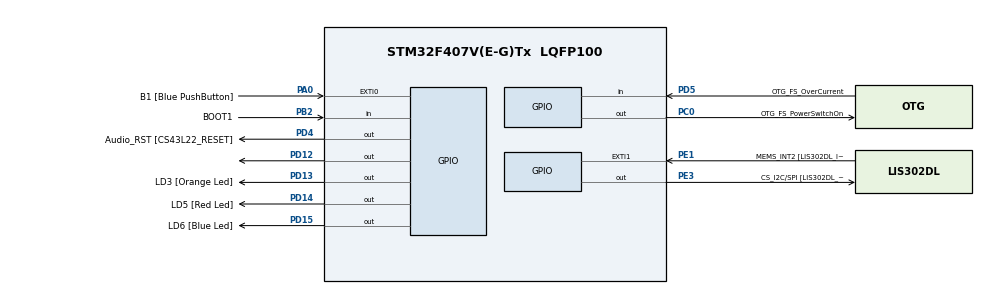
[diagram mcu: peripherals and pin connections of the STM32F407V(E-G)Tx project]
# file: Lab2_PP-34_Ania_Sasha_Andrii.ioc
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Mcu.Family=STM32F4
Mcu.Name=STM32F407V(E-G)Tx
Mcu.Package=LQFP100
NVIC.EXTI0_IRQn=true\:0\:0\:false\:false\:true\:true\:true\:true
NVIC.PriorityGroup=NVIC_PRIORITYGROUP_0
PA0-WKUP.GPIO_Label=B1 [Blue PushButton]
PA0-WKUP.GPIO_ModeDefaultEXTI=GPIO_MODE_IT_RISING_FALLING
PA0-WKUP.Signal=GPXTI0
PA10.GPIO_Label=OTG_FS_ID
PA10.GPIO_Mode=GPIO_MODE_AF_PP
PA10.GPIO_PuPd=GPIO_NOPULL
PA10.GPIO_Speed=GPIO_SPEED_FREQ_LOW
PA10.Signal=USB_OTG_FS_ID
PA11.GPIO_Label=OTG_FS_DM
PA11.GPIO_Mode=GPIO_MODE_AF_PP
PA11.GPIO_PuPd=GPIO_NOPULL
PA11.GPIO_Speed=GPIO_SPEED_FREQ_LOW
PA11.Signal=USB_OTG_FS_DM
PA12.GPIO_Label=OTG_FS_DP
PA12.GPIO_Mode=GPIO_MODE_AF_PP
PA12.GPIO_PuPd=GPIO_NOPULL
PA12.GPIO_Speed=GPIO_SPEED_FREQ_LOW
PA12.Signal=USB_OTG_FS_DP
PA13.GPIO_Label=SWDIO
PA13.Signal=SYS_JTMS-SWDIO
PA14.GPIO_Label=SWCLK
PA14.Signal=SYS_JTCK-SWCLK
PA4.GPIO_Label=I2S3_WS [CS43L22_LRCK]
PA4.GPIO_Mode=GPIO_MODE_AF_PP
PA4.GPIO_PuPd=GPIO_NOPULL
PA4.GPIO_Speed=GPIO_SPEED_FREQ_LOW
PA4.Signal=I2S3_WS
PA5.GPIO_Label=SPI1_SCK [LIS302DL_SCL/SPC]
PA5.GPIO_Mode=GPIO_MODE_AF_PP
PA5.GPIO_PuPd=GPIO_NOPULL
PA5.GPIO_Speed=GPIO_SPEED_FREQ_LOW
PA5.Signal=SPI1_SCK
PA6.GPIO_Label=SPI1_MISO [LIS302DL_SDO]
PA6.GPIO_Mode=GPIO_MODE_AF_PP
PA6.GPIO_PuPd=GPIO_NOPULL
PA6.GPIO_Speed=GPIO_SPEED_FREQ_LOW
PA6.Signal=SPI1_MISO
PA7.GPIO_Label=SPI1_MOSI [LIS302DL_SDA/SDI/SDO]
PA7.GPIO_Mode=GPIO_MODE_AF_PP
PA7.GPIO_PuPd=GPIO_NOPULL
PA7.GPIO_Speed=GPIO_SPEED_FREQ_LOW
PA7.Signal=SPI1_MOSI
PA9.GPIO_Label=VBUS_FS
PA9.GPIO_Mode=GPIO_MODE_INPUT
PA9.GPIO_PuPd=GPIO_NOPULL
PA9.Signal=USB_OTG_FS_VBUS
PB10.GPIO_Label=CLK_IN [MP45DT02_CLK]
PB10.GPIO_Mode=GPIO_MODE_AF_PP
PB10.GPIO_PuPd=GPIO_NOPULL
PB10.GPIO_Speed=GPIO_SPEED_FREQ_LOW
PB10.Signal=I2S2_CK
PB2.GPIO_Label=BOOT1
PB2.GPIO_Mode=GPIO_MODE_INPUT
PB2.GPIO_PuPd=GPIO_NOPULL
PB2.Signal=GPIO_Input
PB3.GPIO_Label=SWO
PB3.Signal=SYS_JTDO-SWO
PB6.GPIO_Label=Audio_SCL [CS43L22_SCL]
PB6.GPIO_Mode=GPIO_MODE_AF_OD
PB6.GPIO_PuPd=GPIO_NOPULL
PB6.GPIO_Speed=GPIO_SPEED_FREQ_LOW
PB6.Signal=I2C1_SCL
PB9.GPIO_Label=Audio_SDA [CS43L22_SDA]
PB9.GPIO_Mode=GPIO_MODE_AF_OD
PB9.GPIO_PuPd=GPIO_NOPULL
PB9.GPIO_Speed=GPIO_SPEED_FREQ_LOW
PB9.Signal=I2C1_SDA
PC0.GPIO_Label=OTG_FS_PowerSwitchOn
PC0.GPIO_PuPd=GPIO_NOPULL
PC0.GPIO_Speed=GPIO_SPEED_FREQ_LOW
PC0.PinState=GPIO_PIN_SET
PC0.Signal=GPIO_Output
PC10.GPIO_Label=I2S3_SCK [CS43L22_SCLK]
PC10.GPIO_Mode=GPIO_MODE_AF_PP
PC10.GPIO_PuPd=GPIO_NOPULL
PC10.GPIO_Speed=GPIO_SPEED_FREQ_LOW
PC10.Signal=I2S3_CK
PC12.GPIO_Label=I2S3_SD [CS43L22_SDIN]
PC12.GPIO_Mode=GPIO_MODE_AF_PP
PC12.GPIO_PuPd=GPIO_NOPULL
PC12.GPIO_Speed=GPIO_SPEED_FREQ_LOW
PC12.Signal=I2S3_SD
PC14-OSC32_IN.GPIO_Label=PC14-OSC32_IN
PC14-OSC32_IN.Mode=LSE-External-Oscillator
PC14-OSC32_IN.Signal=RCC_OSC32_IN
PC15-OSC32_OUT.GPIO_Label=PC15-OSC32_OUT
PC15-OSC32_OUT.Mode=LSE-External-Oscillator
PC15-OSC32_OUT.Signal=RCC_OSC32_OUT
PC3.GPIO_Label=PDM_OUT [MP45DT02_DOUT]
PC3.GPIO_Mode=GPIO_MODE_AF_PP
PC3.GPIO_PuPd=GPIO_NOPULL
PC3.GPIO_Speed=GPIO_SPEED_FREQ_LOW
PC3.Signal=I2S2_SD
PC7.GPIO_Label=I2S3_MCK [CS43L22_MCLK]
PC7.GPIO_Mode=GPIO_MODE_AF_PP
PC7.GPIO_PuPd=GPIO_NOPULL
PC7.GPIO_Speed=GPIO_SPEED_FREQ_LOW
PC7.Signal=I2S3_MCK
PD12.Signal=GPIO_Output
PD13.GPIO_Label=LD3 [Orange Led]
PD13.GPIO_PuPd=GPIO_NOPULL
PD13.GPIO_Speed=GPIO_SPEED_FREQ_LOW
PD13.Signal=GPIO_Output
PD14.GPIO_Label=LD5 [Red Led]
PD14.GPIO_PuPd=GPIO_NOPULL
PD14.GPIO_Speed=GPIO_SPEED_FREQ_LOW
PD14.Signal=GPIO_Output
PD15.GPIO_Label=LD6 [Blue Led]
PD15.GPIO_PuPd=GPIO_NOPULL
PD15.GPIO_Speed=GPIO_SPEED_FREQ_LOW
PD15.Signal=GPIO_Output
PD4.GPIO_Label=Audio_RST [CS43L22_RESET]
PD4.GPIO_PuPd=GPIO_NOPULL
PD4.GPIO_Speed=GPIO_SPEED_FREQ_LOW
PD4.Signal=GPIO_Output
PD5.GPIO_Label=OTG_FS_OverCurrent
PD5.GPIO_Mode=GPIO_MODE_INPUT
PD5.GPIO_PuPd=GPIO_NOPULL
PD5.Signal=GPIO_Input
PE1.GPIO_Label=MEMS_INT2 [LIS302DL_INT2]
PE1.GPIO_ModeDefaultEXTI=GPIO_MODE_EVT_RISING
PE1.GPIO_PuPd=GPIO_NOPULL
PE1.Signal=GPXTI1
PE3.GPIO_Label=CS_I2C/SPI [LIS302DL_CS_I2C/SPI]
PE3.GPIO_PuPd=GPIO_NOPULL
PE3.GPIO_Speed=GPIO_SPEED_FREQ_LOW
PE3.Signal=GPIO_Output
PH0-OSC_IN.GPIO_Label=PH0-OSC_IN
PH0-OSC_IN.Mode=HSE-External-Oscillator
PH0-OSC_IN.Signal=RCC_OSC_IN
PH1-OSC_OUT.GPIO_Label=PH1-OSC_OUT
PH1-OSC_OUT.Mode=HSE-External-Oscillator
PH1-OSC_OUT.Signal=RCC_OSC_OUT
ProjectManager.HeapSize=0x200
ProjectManager.StackSize=0x400
ProjectManager.TargetToolchain=STM32CubeIDE
RCC.48MHZClocksFreq_Value=48000000
RCC.AHBFreq_Value=168000000
RCC.APB1CLKDivider=RCC_HCLK_DIV4
RCC.APB1Freq_Value=42000000
RCC.APB1TimFreq_Value=84000000
RCC.APB2CLKDivider=RCC_HCLK_DIV2
RCC.APB2Freq_Value=84000000
RCC.APB2TimFreq_Value=168000000
RCC.CortexFreq_Value=168000000
RCC.HCLKFreq_Value=168000000
RCC.HSE_VALUE=8000000
RCC.HSI_VALUE=16000000
RCC.PLLM=8
RCC.PLLN=336
RCC.PLLQ=7
RCC.PLLSourceVirtual=RCC_PLLSOURCE_HSE
RCC.SYSCLKFreq_VALUE=168000000
RCC.SYSCLKSource=RCC_SYSCLKSOURCE_PLLCLK
RCC.VCOOutputFreq_Value=336000000
board=STM32F407G-DISC1

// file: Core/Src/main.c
/* USER CODE BEGIN Header */
/**
  ******************************************************************************
  * @file           : main.c
  * @brief          : Main program body
  ******************************************************************************
  * @attention
  *
  * Copyright (c) 2024 STMicroelectronics.
  * All rights reserved.
  *
  * This software is licensed under terms that can be found in the LICENSE file
  * in the root directory of this software component.
  * If no LICENSE file comes with this software, it is provided AS-IS.
  *
  ******************************************************************************
  */
/* USER CODE END Header */
#include "main.h"

uint32_t currentClick = 0;
uint32_t prevClick = 0;
#define debounceTime 200 // Час для усунення брязкоту (в мілісекундах)
uint8_t ledState = 0; // Стан світлодіодів (0 - вимкнені, 1 - всі увімкнені)
uint8_t currentLED = 0; // Поточний активний світлодіод
volatile uint8_t buttonPressed = 0; // Флаг для натискання кнопки

#define NUM_OF_LEDS 4 // Кількість світлодіодів
GPIO_TypeDef* GPIOx = GPIOD; // Порт для світлодіодів
uint16_t LED_PINS[NUM_OF_LEDS] = { GPIO_PIN_12, GPIO_PIN_13, GPIO_PIN_14, GPIO_PIN_15 }; // Піни для кожного світлодіода

void SystemClock_Config(void);
static void MX_GPIO_Init(void);

int main(void)
{
  HAL_Init(); // Ініціалізація HAL

  MX_GPIO_Init(); // Ініціалізація GPIO

  // Вимкнути всі світлодіоди на початку
  HAL_GPIO_WritePin(GPIOx, GPIO_PIN_12 | GPIO_PIN_13 | GPIO_PIN_14 | GPIO_PIN_15, GPIO_PIN_RESET);

  /* Infinite loop */
  while (1)
  {
    // Перевірка натискання кнопки
    if (HAL_GPIO_ReadPin(GPIOA, GPIO_PIN_0) == GPIO_PIN_SET)
    {
      HAL_Delay(debounceTime); // Затримка для уникнення дебаунсу кнопки

      // Логіка почергового вмикання діодів
      if (ledState < NUM_OF_LEDS)
      {
        HAL_GPIO_WritePin(GPIOx, LED_PINS[ledState], GPIO_PIN_SET); // Увімкнути поточний діод
        ledState++;
      }
      else
      {
        // Вимкнути всі діоди і повернути стан до початкового
        HAL_GPIO_WritePin(GPIOx, GPIO_PIN_12 | GPIO_PIN_13 | GPIO_PIN_14 | GPIO_PIN_15, GPIO_PIN_RESET);
        ledState = 0; // Скинути стан
      }

      // Чекати, поки кнопка буде відпущена
      while (HAL_GPIO_ReadPin(GPIOA, GPIO_PIN_0) == GPIO_PIN_SET);
    }
  }
}

/* USER CODE BEGIN 4 */
static void MX_GPIO_Init(void)
{
    GPIO_InitTypeDef GPIO_InitStruct = {0};

    /* GPIO Ports Clock Enable */
    __HAL_RCC_GPIOA_CLK_ENABLE();
    __HAL_RCC_GPIOD_CLK_ENABLE();

    /*Configure GPIO pin : PA0 */
    GPIO_InitStruct.Pin = GPIO_PIN_0;
    GPIO_InitStruct.Mode = GPIO_MODE_IT_RISING_FALLING; // Налаштування переривання
    GPIO_InitStruct.Pull = GPIO_NOPULL;
    HAL_GPIO_Init(GPIOA, &GPIO_InitStruct);

    /*Configure GPIO pins : PD12 PD13 PD14 PD15 */
    GPIO_InitStruct.Pin = GPIO_PIN_12 | GPIO_PIN_13 | GPIO_PIN_14 | GPIO_PIN_15;
    GPIO_InitStruct.Mode = GPIO_MODE_OUTPUT_PP;
    GPIO_InitStruct.Pull = GPIO_NOPULL;
    GPIO_InitStruct.Speed = GPIO_SPEED_FREQ_LOW;
    HAL_GPIO_Init(GPIOD, &GPIO_InitStruct);
}

/* USER CODE END 4 */

void Error_Handler(void)
{
  __disable_irq();
  while (1)
  {
  }
}

/* SystemClock_Config and assert_failed functions remain unchanged */
